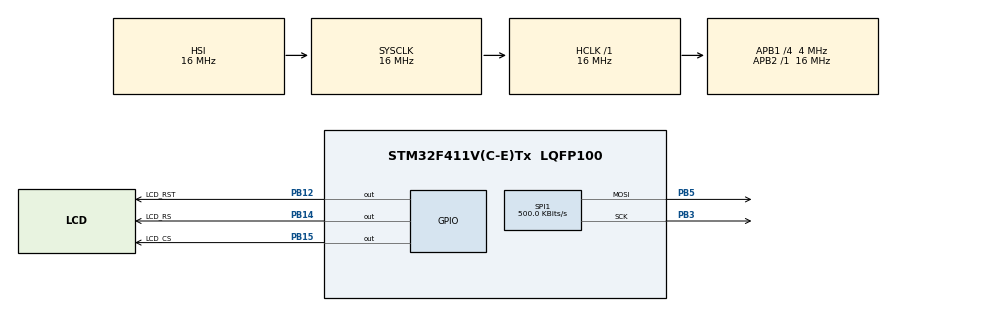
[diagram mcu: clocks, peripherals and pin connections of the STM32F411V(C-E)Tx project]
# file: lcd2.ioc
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Mcu.Family=STM32F4
Mcu.Name=STM32F411V(C-E)Tx
Mcu.Package=LQFP100
NVIC.PriorityGroup=NVIC_PRIORITYGROUP_0
PB12.GPIO_Label=LCD_RST
PB12.Signal=GPIO_Output
PB14.GPIO_Label=LCD_RS
PB14.Signal=GPIO_Output
PB15.GPIO_Label=LCD_CS
PB15.Signal=GPIO_Output
PB3.Mode=TX_Only_Simplex_Unidirect_Master
PB3.Signal=SPI1_SCK
PB5.Mode=TX_Only_Simplex_Unidirect_Master
PB5.Signal=SPI1_MOSI
ProjectManager.HeapSize=0x200
ProjectManager.StackSize=0x400
ProjectManager.TargetToolchain=SW4STM32
RCC.48MHZClocksFreq_Value=48000000
RCC.AHBFreq_Value=16000000
RCC.APB1CLKDivider=RCC_HCLK_DIV4
RCC.APB1Freq_Value=4000000
RCC.APB1TimFreq_Value=8000000
RCC.APB2Freq_Value=16000000
RCC.APB2TimFreq_Value=16000000
RCC.CortexFreq_Value=16000000
RCC.HCLKFreq_Value=16000000
RCC.HSE_VALUE=8000000
RCC.HSI_VALUE=16000000
RCC.PLLI2SM=5
RCC.PLLI2SN=200
RCC.PLLM=8
RCC.PLLP=RCC_PLLP_DIV4
RCC.PLLQ=8
RCC.SYSCLKFreq_VALUE=16000000
RCC.VCOOutputFreq_Value=384000000
SPI1.BaudRatePrescaler=SPI_BAUDRATEPRESCALER_32
SPI1.CalculateBaudRate=500.0 KBits/s
SPI1.Direction=SPI_DIRECTION_2LINES
SPI1.Mode=SPI_MODE_MASTER
SPI1.VirtualType=VM_MASTER
board=STM32F411E-DISCO

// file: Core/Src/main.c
/* USER CODE BEGIN Header */
/**
  ******************************************************************************
  * @file           : main.c
  * @brief          : Main program body
  ******************************************************************************
  * @attention
  *
  * Copyright (c) 2022 STMicroelectronics.
  * All rights reserved.
  *
  * This software is licensed under terms that can be found in the LICENSE file
  * in the root directory of this software component.
  * If no LICENSE file comes with this software, it is provided AS-IS.
  *
  ******************************************************************************
  */
/* USER CODE END Header */
#include "main.h"
#include "spi.h"
#include "gpio.h"
#include "st7735.h"
#include "fonts.h"

// CS 	--> PB15
// AO 	--> PB14
// RST 	--> PB12
// SCK 	-->	PB3
// SDA 	-->	PB5
// LED	-->	3V
// VCC	--> 3V
// GND	--> GND

void SystemClock_Config(void);

int main(void)
{

  /* MCU Configuration--------------------------------------------------------*/

  /* Reset of all peripherals, Initializes the Flash interface and the Systick. */
  HAL_Init();

  /* Configure the system clock */
  SystemClock_Config();

  /* Initialize all configured peripherals */
  MX_GPIO_Init();
  MX_SPI1_Init();
  /* USER CODE BEGIN 2 */
  ST7735_Init();
  ST7735_FillScreen(ST7735_BLACK);
  ST7735_DrawString(1, 0, "CPU=", ST7735_GREEN);
  ST7735_DrawString(1, 1, "Holi", ST7735_RED);
  /* USER CODE END 2 */

  /* Infinite loop */
  while (1)
  {

  }
}

void SystemClock_Config(void)
{
  RCC_OscInitTypeDef RCC_OscInitStruct = {0};
  RCC_ClkInitTypeDef RCC_ClkInitStruct = {0};

  /** Configure the main internal regulator output voltage
  */
  __HAL_RCC_PWR_CLK_ENABLE();
  __HAL_PWR_VOLTAGESCALING_CONFIG(PWR_REGULATOR_VOLTAGE_SCALE1);

  /** Initializes the RCC Oscillators according to the specified parameters
  * in the RCC_OscInitTypeDef structure.
  */
  RCC_OscInitStruct.OscillatorType = RCC_OSCILLATORTYPE_HSI;
  RCC_OscInitStruct.HSIState = RCC_HSI_ON;
  RCC_OscInitStruct.HSICalibrationValue = RCC_HSICALIBRATION_DEFAULT;
  RCC_OscInitStruct.PLL.PLLState = RCC_PLL_NONE;
  if (HAL_RCC_OscConfig(&RCC_OscInitStruct) != HAL_OK)
  {
    Error_Handler();
  }

  /** Initializes the CPU, AHB and APB buses clocks
  */
  RCC_ClkInitStruct.ClockType = RCC_CLOCKTYPE_HCLK|RCC_CLOCKTYPE_SYSCLK
                              |RCC_CLOCKTYPE_PCLK1|RCC_CLOCKTYPE_PCLK2;
  RCC_ClkInitStruct.SYSCLKSource = RCC_SYSCLKSOURCE_HSI;
  RCC_ClkInitStruct.AHBCLKDivider = RCC_SYSCLK_DIV1;
  RCC_ClkInitStruct.APB1CLKDivider = RCC_HCLK_DIV4;
  RCC_ClkInitStruct.APB2CLKDivider = RCC_HCLK_DIV1;

  if (HAL_RCC_ClockConfig(&RCC_ClkInitStruct, FLASH_LATENCY_0) != HAL_OK)
  {
    Error_Handler();
  }
}

void Error_Handler(void)
{
  __disable_irq();
  while (1)
  {
  }
}
